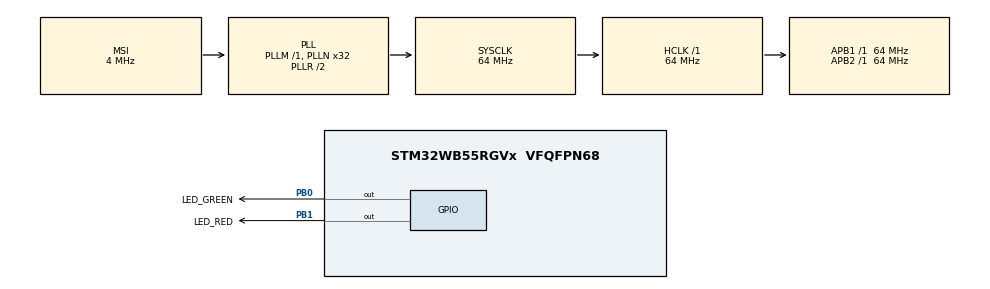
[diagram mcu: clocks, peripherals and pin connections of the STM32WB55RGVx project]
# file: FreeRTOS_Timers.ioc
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FREERTOS.HEAP_NUMBER=4
FREERTOS.INCLUDE_eTaskGetState=1
FREERTOS.INCLUDE_pcTaskGetTaskName=0
FREERTOS.INCLUDE_uxTaskGetStackHighWaterMark=1
FREERTOS.INCLUDE_uxTaskPriorityGet=1
FREERTOS.INCLUDE_vTaskCleanUpResources=0
FREERTOS.INCLUDE_vTaskDelay=1
FREERTOS.INCLUDE_vTaskDelayUntil=1
FREERTOS.INCLUDE_vTaskDelete=1
FREERTOS.INCLUDE_vTaskPrioritySet=1
FREERTOS.INCLUDE_vTaskSuspend=1
FREERTOS.INCLUDE_xEventGroupSetBitFromISR=0
FREERTOS.INCLUDE_xQueueGetMutexHolder=1
FREERTOS.INCLUDE_xSemaphoreGetMutexHolder=0
FREERTOS.INCLUDE_xTaskAbortDelay=0
FREERTOS.INCLUDE_xTaskGetCurrentTaskHandle=1
FREERTOS.INCLUDE_xTaskGetHandle=0
FREERTOS.INCLUDE_xTaskGetSchedulerState=1
FREERTOS.INCLUDE_xTaskResumeFromISR=1
FREERTOS.INCLUDE_xTimerPendFunctionCall=1
FREERTOS.MEMORY_ALLOCATION=0
FREERTOS.Tasks01=LEDThread,24,128,ToggleLEDsThread,Default,NULL,Dynamic,NULL,NULL
FREERTOS.Timers01=LEDTimer,osTimerCallback,osTimerPeriodic,Default,NULL,Dynamic,NULL
FREERTOS.configCHECK_FOR_STACK_OVERFLOW=0
FREERTOS.configENABLE_BACKWARD_COMPATIBILITY=1
FREERTOS.configGENERATE_RUN_TIME_STATS=0
FREERTOS.configIDLE_SHOULD_YIELD=1
FREERTOS.configLIBRARY_LOWEST_INTERRUPT_PRIORITY=15
FREERTOS.configLIBRARY_MAX_SYSCALL_INTERRUPT_PRIORITY=5
FREERTOS.configMAX_CO_ROUTINE_PRIORITIES=2
FREERTOS.configMAX_PRIORITIES=56
FREERTOS.configMAX_TASK_NAME_LEN=16
FREERTOS.configMINIMAL_STACK_SIZE=128
FREERTOS.configQUEUE_REGISTRY_SIZE=8
FREERTOS.configRECORD_STACK_HIGH_ADDRESS=0
FREERTOS.configTICK_RATE_HZ=1000
FREERTOS.configTIMER_QUEUE_LENGTH=10
FREERTOS.configTIMER_TASK_PRIORITY=2
FREERTOS.configTIMER_TASK_STACK_DEPTH=256
FREERTOS.configTOTAL_HEAP_SIZE=3072
FREERTOS.configUSE_APPLICATION_TASK_TAG=0
FREERTOS.configUSE_COUNTING_SEMAPHORES=1
FREERTOS.configUSE_CO_ROUTINES=0
FREERTOS.configUSE_DAEMON_TASK_STARTUP_HOOK=0
FREERTOS.configUSE_IDLE_HOOK=0
FREERTOS.configUSE_MALLOC_FAILED_HOOK=0
FREERTOS.configUSE_MUTEXES=1
FREERTOS.configUSE_PREEMPTION=1
FREERTOS.configUSE_RECURSIVE_MUTEXES=1
FREERTOS.configUSE_STATS_FORMATTING_FUNCTIONS=0
FREERTOS.configUSE_TASK_NOTIFICATIONS=1
FREERTOS.configUSE_TICKLESS_IDLE=0
FREERTOS.configUSE_TICK_HOOK=0
FREERTOS.configUSE_TIMERS=1
FREERTOS.configUSE_TRACE_FACILITY=1
Mcu.Family=STM32WB
Mcu.Name=STM32WB55RGVx
Mcu.Package=VFQFPN68
NVIC.PriorityGroup=NVIC_PRIORITYGROUP_4
NVIC.TIM1_TRG_COM_TIM17_IRQn=true\:0\:0\:false\:false\:true\:false\:false\:true\:true
NVIC.TimeBase=TIM1_TRG_COM_TIM17_IRQn
NVIC.TimeBaseIP=TIM17
PB0.GPIO_Label=LED_GREEN
PB0.Signal=GPIO_Output
PB1.GPIO_Label=LED_RED
PB1.Signal=GPIO_Output
ProjectManager.HeapSize=0x200
ProjectManager.StackSize=0x400
ProjectManager.TargetToolchain=EWARM V9.60
RCC.ADCFreq_Value=16000000
RCC.AHB2CLKDivider=RCC_SYSCLK_DIV2
RCC.AHBFreq_Value=64000000
RCC.APB1Freq_Value=64000000
RCC.APB1TimFreq_Value=64000000
RCC.APB2Freq_Value=64000000
RCC.APB2TimFreq_Value=64000000
RCC.APB3Freq_Value=16000000
RCC.CodegenConfigPeriph=false
RCC.CortexFreq_Value=64000000
RCC.HCLKFreq_Value=64000000
RCC.HSE_VALUE=8000000
RCC.HSI48_VALUE=48000000
RCC.HSI_VALUE=16000000
RCC.LSE_VALUE=32768
RCC.MSI_VALUE=4000000
RCC.PLLN=32
RCC.PLLP=RCC_PLLP_DIV5
RCC.PLLQ=RCC_PLLQ_DIV4
RCC.SMPSDivider=1
RCC.SYSCLKFreq_VALUE=64000000
RCC.SYSCLKSource=RCC_SYSCLKSOURCE_PLLCLK
RCC.USBFreq_Value=16000000
RCC.VCOOutputFreq_Value=128000000
VP_FREERTOS_VS_CMSIS_V2.Mode=CMSIS_V2
VP_MEMORYMAP_VS_MEMORYMAP.Mode=CurAppReg
VP_SYS_VS_tim17.Mode=TIM17
board=custom

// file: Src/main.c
/* USER CODE BEGIN Header */
/**
  ******************************************************************************
  * @file    FreeRTOS\FreeRTOS_Timers\Src\main.c
  * @author  MCD Application Team
  * @brief   Main program body
  ******************************************************************************
  * @attention
  *
  * Copyright (c) 2019-2021 STMicroelectronics.
  * All rights reserved.
  *
  * This software is licensed under terms that can be found in the LICENSE file
  * in the root directory of this software component.
  * If no LICENSE file comes with this software, it is provided AS-IS.
  *
  ******************************************************************************
  */
/* USER CODE END Header */
#include "main.h"
#include "cmsis_os2.h"
#include "FreeRTOS.h"

/* Definitions for LEDThread */
osThreadId_t LEDThreadHandle;
const osThreadAttr_t LEDThread_attributes = {
  .name = "LEDThread",
  .priority = (osPriority_t) osPriorityNormal,
  .stack_size = 128 * 4
};
/* Definitions for LEDTimer */
osTimerId_t LEDTimerHandle;
const osTimerAttr_t LEDTimer_attributes = {
  .name = "LEDTimer"
};
/* USER CODE BEGIN PV */
__IO uint32_t TimeCounter = 0;
/* USER CODE END PV */

void SystemClock_Config(void);
static void MX_GPIO_Init(void);
void ToggleLEDsThread(void *argument);
void osTimerCallback(void *argument);

int main(void)
{

  /* USER CODE BEGIN 1 */
  /* STM32WBxx HAL library initialization:
       - Configure the Flash prefetch
       - Systick timer is configured by default as source of time base, but user
         can eventually implement his proper time base source (a general purpose
         timer for example or other time source), keeping in mind that Time base
         duration should be kept 1ms since PPP_TIMEOUT_VALUEs are defined and
         handled in milliseconds basis.
       - Set NVIC Group Priority to 4
       - Low Level Initialization
     */
  /* USER CODE END 1 */

  /* MCU Configuration--------------------------------------------------------*/

  /* Reset of all peripherals, Initializes the Flash interface and the Systick. */
  HAL_Init();

  /* Configure the system clock */
  SystemClock_Config();

  /* Initialize all configured peripherals */
  MX_GPIO_Init();

  /* Init scheduler */
  osKernelInitialize();

  /* Create the timer(s) */
  /* creation of LEDTimer */
  LEDTimerHandle = osTimerNew(osTimerCallback, osTimerPeriodic, NULL, &LEDTimer_attributes);

  /* USER CODE BEGIN RTOS_TIMERS */
  if(LEDTimerHandle == NULL)
  {
    Error_Handler();
  }
  osTimerStart(LEDTimerHandle, 200);
  /* USER CODE END RTOS_TIMERS */

  /* Create the thread(s) */
  /* creation of LEDThread */
  LEDThreadHandle = osThreadNew(ToggleLEDsThread, NULL, &LEDThread_attributes);

  /* USER CODE BEGIN RTOS_THREADS */
  if(LEDThreadHandle == NULL)
  {
    Error_Handler();
  }
  /* USER CODE END RTOS_THREADS */

  /* Start scheduler */
  osKernelStart();

  /* We should never get here as control is now taken by the scheduler */

  /* Infinite loop */
  while (1)
  {

  }
}

void SystemClock_Config(void)
{
  RCC_OscInitTypeDef RCC_OscInitStruct = {0};
  RCC_ClkInitTypeDef RCC_ClkInitStruct = {0};

  /** Configure the main internal regulator output voltage
  */
  __HAL_PWR_VOLTAGESCALING_CONFIG(PWR_REGULATOR_VOLTAGE_SCALE1);

  /** Initializes the RCC Oscillators according to the specified parameters
  * in the RCC_OscInitTypeDef structure.
  */
  RCC_OscInitStruct.OscillatorType = RCC_OSCILLATORTYPE_MSI;
  RCC_OscInitStruct.MSIState = RCC_MSI_ON;
  RCC_OscInitStruct.MSICalibrationValue = RCC_MSICALIBRATION_DEFAULT;
  RCC_OscInitStruct.MSIClockRange = RCC_MSIRANGE_6;
  RCC_OscInitStruct.PLL.PLLState = RCC_PLL_ON;
  RCC_OscInitStruct.PLL.PLLSource = RCC_PLLSOURCE_MSI;
  RCC_OscInitStruct.PLL.PLLM = RCC_PLLM_DIV1;
  RCC_OscInitStruct.PLL.PLLN = 32;
  RCC_OscInitStruct.PLL.PLLP = RCC_PLLP_DIV5;
  RCC_OscInitStruct.PLL.PLLR = RCC_PLLR_DIV2;
  RCC_OscInitStruct.PLL.PLLQ = RCC_PLLQ_DIV4;
  if (HAL_RCC_OscConfig(&RCC_OscInitStruct) != HAL_OK)
  {
    Error_Handler();
  }

  /** Configure the SYSCLKSource, HCLK, PCLK1 and PCLK2 clocks dividers
  */
  RCC_ClkInitStruct.ClockType = RCC_CLOCKTYPE_HCLK4|RCC_CLOCKTYPE_HCLK2
                              |RCC_CLOCKTYPE_HCLK|RCC_CLOCKTYPE_SYSCLK
                              |RCC_CLOCKTYPE_PCLK1|RCC_CLOCKTYPE_PCLK2;
  RCC_ClkInitStruct.SYSCLKSource = RCC_SYSCLKSOURCE_PLLCLK;
  RCC_ClkInitStruct.AHBCLKDivider = RCC_SYSCLK_DIV1;
  RCC_ClkInitStruct.APB1CLKDivider = RCC_HCLK_DIV1;
  RCC_ClkInitStruct.APB2CLKDivider = RCC_HCLK_DIV1;
  RCC_ClkInitStruct.AHBCLK2Divider = RCC_SYSCLK_DIV2;
  RCC_ClkInitStruct.AHBCLK4Divider = RCC_SYSCLK_DIV1;

  if (HAL_RCC_ClockConfig(&RCC_ClkInitStruct, FLASH_LATENCY_3) != HAL_OK)
  {
    Error_Handler();
  }
}

static void MX_GPIO_Init(void)
{
  GPIO_InitTypeDef GPIO_InitStruct = {0};

  /* GPIO Ports Clock Enable */
  __HAL_RCC_GPIOB_CLK_ENABLE();

  /*Configure GPIO pin Output Level */
  HAL_GPIO_WritePin(GPIOB, LED_GREEN_Pin|LED_RED_Pin, GPIO_PIN_RESET);

  /*Configure GPIO pins : LED_GREEN_Pin LED_RED_Pin */
  GPIO_InitStruct.Pin = LED_GREEN_Pin|LED_RED_Pin;
  GPIO_InitStruct.Mode = GPIO_MODE_OUTPUT_PP;
  GPIO_InitStruct.Pull = GPIO_NOPULL;
  GPIO_InitStruct.Speed = GPIO_SPEED_FREQ_LOW;
  HAL_GPIO_Init(GPIOB, &GPIO_InitStruct);

}

void ToggleLEDsThread(void *argument)
{
  /* USER CODE BEGIN 5 */
  (void) argument;
  /* Infinite loop */
  for(;;)
  {
    /* Toggle LED_GREEN each 400ms */
    HAL_GPIO_TogglePin(LED_GREEN_GPIO_Port, LED_GREEN_Pin);
    osDelay(400);
  }
  /* USER CODE END 5 */
}

/* osTimerCallback function */
void osTimerCallback(void *argument)
{
  /* USER CODE BEGIN osTimerCallback */
  (void) argument;

  /* Toggle LED_RED*/
  HAL_GPIO_TogglePin(LED_RED_GPIO_Port, LED_RED_Pin);
  if (TimeCounter == 25)
  {
      TimeCounter = 0;
  }
  /* USER CODE END osTimerCallback */
}

void HAL_TIM_PeriodElapsedCallback(TIM_HandleTypeDef *htim)
{
  if (htim->Instance == TIM17)
  {
    HAL_IncTick();
  }
}

void Error_Handler(void)
{
  while (1)
  {
  }
}
